AUTOSAR XML (schema 4-1-3)
standard types defined: boolean, uint16, boolean_CompuMethod, boolean_DataConstr, uint16_DataConstr, sint16, uint32, uint8
package /DataTypes
  impl type rt_Arry_uint16_10: category=ARRAY
    element rt_Arry_uint16_10: array-size=10, array-size-semantics=FIXED-SIZE, implementation-data-type=ImplementationDataTypes/uint16
package /RB/ApplicationSW/PT/ApplicationDataTypes
  application array data type rt_Array_U_q0p01_V_s16_10: category=ARRAY, sw-calibration-access=READ-WRITE
    element rt_Array_U_q0p01_V_s16_10: category=VALUE, type=U_q0p01_V_s16, array-size-semantics=FIXED-SIZE, max-number-of-elements=10
package /RB/ApplicationSW/PT/CompuMethods
  compu method CM_boolean: 0=FALSE, 1=TRUE
package /RB/ApplicationSW/PT/Constants
  12 x constant specification:
    EPBCalprDrvr_stPwrStgIndexStrt_C: value-spec=EPBCalprDrvr_stPwrStgIndexStrt_C:3
    EPBCalprDrvr_uAplySh2VoltMax_C: value-spec=0.5 V
    EPBCalprDrvr_uAplySh2VoltMin_C: value-spec=0 V
    EPBCalprDrvr_uHBrigVoltOffSet_C: value-spec=1 V
    EPBCalprDrvr_uPwrSuplyMax_C: value-spec=16 V
    EPBCalprDrvr_uPwrSuplyMin_C: value-spec=9 V
    EPBCalprDrvr_uRelsSh1VoltMax_C: value-spec=0.5 V
    EPBCalprDrvr_uRelsSh1VoltMin_C: value-spec=0 V
    EPBCalprDrvr_uStopSh1VoltMax_C: value-spec=0.5 V
    EPBCalprDrvr_uStopSh1VoltMin_C: value-spec=0 V
    EPBCalprDrvr_uStopSh2VoltMax_C: value-spec=0.5 V
    EPBCalprDrvr_uStopSh2VoltMin_C: value-spec=0 V
package /RB/ApplicationSW/PT/DataConstrs
  range DC_uint16: raw 0..65535
package /RB/ApplicationSW/PT/ImplementationDataTypes
  impl type rt_Array_sint16_10: category=ARRAY
    element rt_Array_sint16_10: array-size=10, array-size-semantics=FIXED-SIZE, implementation-data-type=sint16
  impl type rt_Array_uint32_2: category=ARRAY
    element rt_Array_uint32_2: array-size=2, array-size-semantics=FIXED-SIZE, implementation-data-type=uint32
package /RB/ApplicationSW/PT/Units
  unit NoUnit: factor-si-to-unit=1, offset-si-to-unit=0
package /SwAddrMethods
  sw addr method CALDATA_SWC: memory-allocation-keyword-policy=ADDR-METHOD-SHORT-NAME
package /UAES/ASW/ApplicationDataType
  4 x application array data type, all with category=ARRAY, sw-calibration-access=READ-WRITE:
    Array_Curr_q0p01_A_s16_10
      element Array_Curr_q0p01_A_s16_10: category=VALUE, type=Curr_q0p01_A_s16, array-size-semantics=FIXED-SIZE, max-number-of-elements=10
    Array_Curr_q0p01_A_u16_10
      element Array_Curr_q0p01_A_u16_10: category=VALUE, type=Curr_q0p01_A_u16, array-size-semantics=FIXED-SIZE, max-number-of-elements=10
    Array_U_q0p01_V_s16_10
      element Array_U_q0p01_V_s16_10: category=VALUE, type=U_q0p01_V_s16, array-size-semantics=FIXED-SIZE, max-number-of-elements=10
    Array_U_q0p01_V_u16_10
      element Array_U_q0p01_V_u16_10: category=VALUE, type=U_q0p01_V_u16, array-size-semantics=FIXED-SIZE, max-number-of-elements=10
  4 x app type, all with category=VALUE, sw-calibration-access=READ-WRITE:
    Curr_q0p01_A_s16: compu {phys=raw*0.01; unit A}, range phys -327.68..327.67
    Curr_q0p01_A_u16: compu {phys=raw*0.01; unit A}, range phys 0..655.35
    U_q0p01_V_s16: compu {phys=raw*0.01; unit V}, range phys -327.68..327.67
    U_q0p01_V_u16: compu {phys=raw*0.01; unit V}, range phys 0..655.35
package /UAES/ASW/DataConstrs
  range DC_boolean: raw 0..1
  range DC_sint16: raw -32768..32767
  range DC_uint16: raw 0..65535
  range DC_uint32: raw 0..4294967295
  range DC_uint8: raw 0..255
package /UAES/ASW/DataTypeMappingSets
  data type mapping set DTMS_EPBCalprDrvr_PwrStgFb
    data-type-maps:
      application-data-type=rt_Array_U_q0p01_V_s16_10, implementation-data-type=rt_Array_sint16_10
      application-data-type=Array_Curr_q0p01_A_s16_10, implementation-data-type=Array_sint16_10
      application-data-type=Array_Curr_q0p01_A_u16_10, implementation-data-type=Array_uint16_10
      application-data-type=Array_U_q0p01_V_s16_10, implementation-data-type=Array_sint16_10
      application-data-type=Array_U_q0p01_V_u16_10, implementation-data-type=Array_uint16_10
      application-data-type=Curr_q0p01_A_s16, implementation-data-type=sint16
      application-data-type=Curr_q0p01_A_u16, implementation-data-type=ImplementationDataTypes/uint16
      application-data-type=U_q0p01_V_s16, implementation-data-type=sint16
      application-data-type=U_q0p01_V_u16, implementation-data-type=ImplementationDataTypes/uint16
package /UAES/ASW/ImplementationDataTypes
  impl type Array_sint16_10: category=ARRAY
    element Array_sint16_10: array-size=10, array-size-semantics=FIXED-SIZE, implementation-data-type=sint16
  impl type Array_uint16_10: category=ARRAY
    element Array_uint16_10: array-size=10, array-size-semantics=FIXED-SIZE, implementation-data-type=ImplementationDataTypes/uint16
  impl type Array_uint32_2: category=ARRAY
    element Array_uint32_2: array-size=2, array-size-semantics=FIXED-SIZE, implementation-data-type=uint32
package /UAES/ASW/PortInterfaces
  client server interface IoHwAb_EPBHb
    9 x operation, all with possible-error=E_NOT_OK:
      Get_AD_Valid
        arg EPB_AD_Valid: category=VALUE, type=ImplementationDataTypes/boolean, direction=OUT
      Get_CS1_Val
        arg cs1_Val: category=ARRAY, type=rt_Arry_uint16_10, direction=OUT
      Get_CS2_Val
        arg cs2_Val: category=ARRAY, type=rt_Arry_uint16_10, direction=OUT
      Get_Diag
        arg EPBDiag_status: category=ARRAY, type=Array_uint32_2, direction=OUT
      Get_SH1_Val
        arg sh1_Val: category=ARRAY, type=Array_uint16_10, direction=OUT
      Get_SH2_Val
        arg sh2_Val: category=ARRAY, type=Array_uint16_10, direction=OUT
      Get_uBridge_Val
        arg uBridge_Val: category=ARRAY, type=Array_uint16_10, direction=OUT
      Set_Mod
        arg Hb_Mod: category=VALUE, type=uint8, direction=IN
      Set_Safemod
        arg Safemode_Mod: category=VALUE, type=ImplementationDataTypes/boolean, direction=IN
    error E_NOT_OK: error-code=1
  25 x sender receiver interface:
    EPBCalprDrvr_CurrMotDrvrCurr_a: invalidation-policy{data-element=EPBCalprDrvr_CurrMotDrvrCurr_a/Val, handle-invalid=DONT-INVALIDATE}
      data Val: category=ARRAY, sw-calibration-access=READ-ONLY, type=Array_Curr_q0p01_A_s16_10
    EPBCalprDrvr_CurrMotDrvrCurr_a_V3: invalidation-policy{data-element=EPBCalprDrvr_CurrMotDrvrCurr_a_V3/Val, handle-invalid=DONT-INVALIDATE}
      data Val: category=ARRAY, sw-calibration-access=READ-ONLY, type=Array_Curr_q0p01_A_u16_10
    EPBCalprDrvr_CurrMotDrvrCurrLocl_a: invalidation-policy{data-element=EPBCalprDrvr_CurrMotDrvrCurrLocl_a/Val, handle-invalid=DONT-INVALIDATE}
      data Val: category=ARRAY, sw-calibration-access=READ-ONLY, type=Array_Curr_q0p01_A_u16_10
    EPBCalprDrvr_flgCalprLineErrDeb: invalidation-policy{data-element=EPBCalprDrvr_flgCalprLineErrDeb/Val, handle-invalid=DONT-INVALIDATE}
      data Val: category=VALUE, sw-calibration-access=READ-ONLY, type=ImplementationDataTypes/boolean
    EPBCalprDrvr_flgCalprOLErrDeb: invalidation-policy{data-element=EPBCalprDrvr_flgCalprOLErrDeb/Val, handle-invalid=DONT-INVALIDATE}
      data Val: category=VALUE, sw-calibration-access=READ-ONLY, type=ImplementationDataTypes/boolean
    EPBCalprDrvr_flgCalprSCBErrDeb: invalidation-policy{data-element=EPBCalprDrvr_flgCalprSCBErrDeb/Val, handle-invalid=DONT-INVALIDATE}
      data Val: category=VALUE, sw-calibration-access=READ-ONLY, type=ImplementationDataTypes/boolean
    EPBCalprDrvr_flgCalprSCGErrDeb: invalidation-policy{data-element=EPBCalprDrvr_flgCalprSCGErrDeb/Val, handle-invalid=DONT-INVALIDATE}
      data Val: category=VALUE, sw-calibration-access=READ-ONLY, type=ImplementationDataTypes/boolean
    EPBCalprDrvr_flgClsdDrvrMos: invalidation-policy{data-element=EPBCalprDrvr_flgClsdDrvrMos/Val, handle-invalid=DONT-INVALIDATE}
      data Val: category=VALUE, sw-calibration-access=READ-ONLY, type=ImplementationDataTypes/boolean
    EPBCalprDrvr_flgHbrigLineErrDeb: invalidation-policy{data-element=EPBCalprDrvr_flgHbrigLineErrDeb/Val, handle-invalid=DONT-INVALIDATE}
      data Val: category=VALUE, sw-calibration-access=READ-ONLY, type=ImplementationDataTypes/boolean
    EPBCalprDrvr_flgHmiYelLmpOn: invalidation-policy{data-element=EPBCalprDrvr_flgHmiYelLmpOn/Val, handle-invalid=DONT-INVALIDATE}
      data Val: category=VALUE, sw-calibration-access=READ-ONLY, type=ImplementationDataTypes/boolean
    EPBCalprDrvr_flgRvpgOLErrDeb: invalidation-policy{data-element=EPBCalprDrvr_flgRvpgOLErrDeb/Val, handle-invalid=DONT-INVALIDATE}
      data Val: category=VALUE, sw-calibration-access=READ-ONLY, type=ImplementationDataTypes/boolean
    EPBCalprDrvr_flgRvpgPlsErrDeb: invalidation-policy{data-element=EPBCalprDrvr_flgRvpgPlsErrDeb/Val, handle-invalid=DONT-INVALIDATE}
      data Val: category=VALUE, sw-calibration-access=READ-ONLY, type=ImplementationDataTypes/boolean
    EPBCalprDrvr_stHostAvl: invalidation-policy{data-element=EPBCalprDrvr_stHostAvl/Val, handle-invalid=DONT-INVALIDATE}
      data Val: category=VALUE, sw-calibration-access=READ-ONLY, type=uint8
    EPBCalprDrvr_stHwDrvrCmd: invalidation-policy{data-element=EPBCalprDrvr_stHwDrvrCmd/Val, handle-invalid=DONT-INVALIDATE}
      data Val: category=VALUE, sw-calibration-access=READ-ONLY, type=uint8
    EPBCalprDrvr_stMosOffJudg: invalidation-policy{data-element=EPBCalprDrvr_stMosOffJudg/Val, handle-invalid=DONT-INVALIDATE}
      data Val: category=VALUE, sw-calibration-access=READ-ONLY, type=uint8
    EPBCalprDrvr_stMotDrvrSt: invalidation-policy{data-element=EPBCalprDrvr_stMotDrvrSt/Val, handle-invalid=DONT-INVALIDATE}
      data Val: category=VALUE, sw-calibration-access=READ-ONLY, type=uint8
    EPBCalprDrvr_stPwrSplySt: invalidation-policy{data-element=EPBCalprDrvr_stPwrSplySt/Val, handle-invalid=DONT-INVALIDATE}
      data Val: category=VALUE, sw-calibration-access=READ-ONLY, type=uint8
    EPBCalprDrvr_uHBrigVolt_a: invalidation-policy{data-element=EPBCalprDrvr_uHBrigVolt_a/Val, handle-invalid=DONT-INVALIDATE}
      data Val: category=ARRAY, sw-calibration-access=READ-ONLY, type=Array_U_q0p01_V_u16_10
    EPBCalprDrvr_uMotDrvrSplyAvrgVolt: invalidation-policy{data-element=EPBCalprDrvr_uMotDrvrSplyAvrgVolt/Val, handle-invalid=DONT-INVALIDATE}
      data Val: category=VALUE, sw-calibration-access=READ-ONLY, type=U_q0p01_V_u16
    EPBCalprDrvr_uMotDrvrSuplyVolt: invalidation-policy{data-element=EPBCalprDrvr_uMotDrvrSuplyVolt/Val, handle-invalid=DONT-INVALIDATE}
      data Val: category=VALUE, sw-calibration-access=READ-ONLY, type=U_q0p01_V_s16
    EPBCalprDrvr_uMotDrvrSuplyVolt_V3: invalidation-policy{data-element=EPBCalprDrvr_uMotDrvrSuplyVolt_V3/Val, handle-invalid=DONT-INVALIDATE}
      data Val: category=VALUE, sw-calibration-access=READ-ONLY, type=U_q0p01_V_u16
    EPBCalprDrvr_uMotDrvrVolt_a: invalidation-policy{data-element=EPBCalprDrvr_uMotDrvrVolt_a/Val, handle-invalid=DONT-INVALIDATE}
      data Val: category=ARRAY, sw-calibration-access=READ-ONLY, type=Array_U_q0p01_V_s16_10
    EPBCalprDrvr_uMotDrvrVoltLocl_a: invalidation-policy{data-element=EPBCalprDrvr_uMotDrvrVoltLocl_a/Val, handle-invalid=DONT-INVALIDATE}
      data Val: category=ARRAY, sw-calibration-access=READ-ONLY, type=rt_Array_U_q0p01_V_s16_10
    EPBCalprDrvr_uSh1Volt_a: invalidation-policy{data-element=EPBCalprDrvr_uSh1Volt_a/Val, handle-invalid=DONT-INVALIDATE}
      data Val: category=ARRAY, sw-calibration-access=READ-ONLY, type=Array_U_q0p01_V_u16_10
    EPBCalprDrvr_uSh2Volt_a: invalidation-policy{data-element=EPBCalprDrvr_uSh2Volt_a/Val, handle-invalid=DONT-INVALIDATE}
      data Val: category=ARRAY, sw-calibration-access=READ-ONLY, type=Array_U_q0p01_V_u16_10
package /UAES/ASW/SwComponentTypes
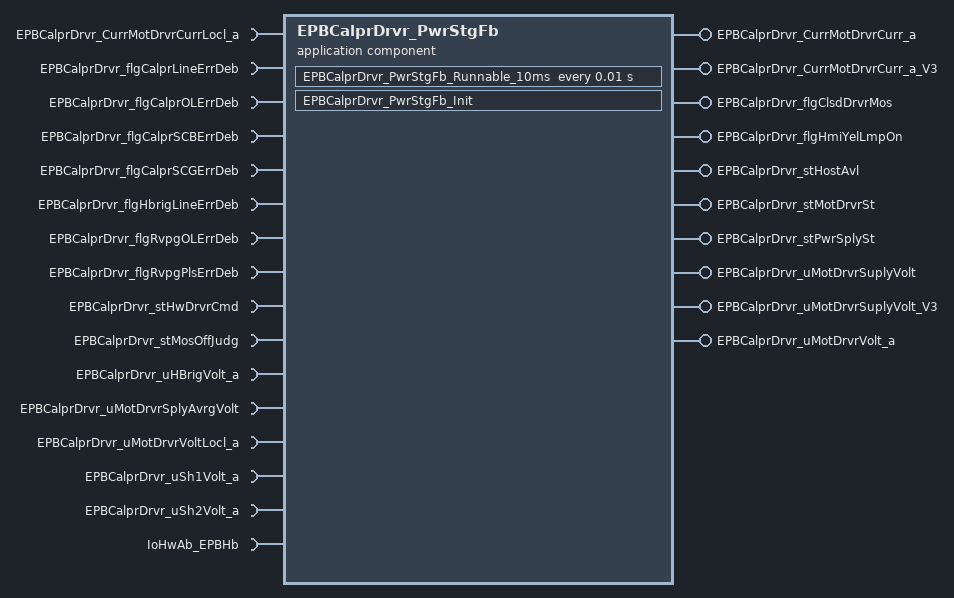
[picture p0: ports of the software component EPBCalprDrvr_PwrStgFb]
  application sw component type EPBCalprDrvr_PwrStgFb
    15 x require port:
      EPBCalprDrvr_CurrMotDrvrCurrLocl_a: nonqueued-receiver-com-spec{data-element=EPBCalprDrvr_CurrMotDrvrCurrLocl_a/Val, init-value=ComSpec04d326f9_854a79bc9e8ec665:10 x 0 A}, required-interface=EPBCalprDrvr_CurrMotDrvrCurrLocl_a
      EPBCalprDrvr_flgCalprLineErrDeb: nonqueued-receiver-com-spec{data-element=EPBCalprDrvr_flgCalprLineErrDeb/Val, init-value=ComSpec28eb8dd6_df283335803d315d:0}, required-interface=EPBCalprDrvr_flgCalprLineErrDeb
      EPBCalprDrvr_flgCalprOLErrDeb: nonqueued-receiver-com-spec{data-element=EPBCalprDrvr_flgCalprOLErrDeb/Val, init-value=ComSpeccc5a8cb5_4ed6c4668107c573:0}, required-interface=EPBCalprDrvr_flgCalprOLErrDeb
      EPBCalprDrvr_flgCalprSCBErrDeb: nonqueued-receiver-com-spec{data-element=EPBCalprDrvr_flgCalprSCBErrDeb/Val, init-value=ComSpeca196ac7a_66588703c52717d2:0}, required-interface=EPBCalprDrvr_flgCalprSCBErrDeb
      EPBCalprDrvr_flgCalprSCGErrDeb: nonqueued-receiver-com-spec{data-element=EPBCalprDrvr_flgCalprSCGErrDeb/Val, init-value=ComSpec815de22e_a43baf1ed2a030f3:0}, required-interface=EPBCalprDrvr_flgCalprSCGErrDeb
      EPBCalprDrvr_flgHbrigLineErrDeb: nonqueued-receiver-com-spec{data-element=EPBCalprDrvr_flgHbrigLineErrDeb/Val, init-value=ComSpec127366cc_e0cde48bb889a4e3:0}, required-interface=EPBCalprDrvr_flgHbrigLineErrDeb
      EPBCalprDrvr_flgRvpgOLErrDeb: nonqueued-receiver-com-spec{data-element=EPBCalprDrvr_flgRvpgOLErrDeb/Val, init-value=ComSpecedb32ece_dd05006a6dd768e6:0}, required-interface=EPBCalprDrvr_flgRvpgOLErrDeb
      EPBCalprDrvr_flgRvpgPlsErrDeb: nonqueued-receiver-com-spec{data-element=EPBCalprDrvr_flgRvpgPlsErrDeb/Val, init-value=ComSpecc3518dfb_07155b8be003ef41:0}, required-interface=EPBCalprDrvr_flgRvpgPlsErrDeb
      EPBCalprDrvr_stHwDrvrCmd: nonqueued-receiver-com-spec{data-element=EPBCalprDrvr_stHwDrvrCmd/Val, init-value=ComSpecf8dcf647_531a9a3c52d64e93:0}, required-interface=EPBCalprDrvr_stHwDrvrCmd
      EPBCalprDrvr_stMosOffJudg: nonqueued-receiver-com-spec{data-element=EPBCalprDrvr_stMosOffJudg/Val, init-value=ComSpec50af7012_f1fd4a6c0907b34b:0}, required-interface=EPBCalprDrvr_stMosOffJudg
      EPBCalprDrvr_uHBrigVolt_a: nonqueued-receiver-com-spec{data-element=EPBCalprDrvr_uHBrigVolt_a/Val, init-value=ComSpece093ef3e_f51da5a2f3bbfbb1:10 x 0 V}, required-interface=EPBCalprDrvr_uHBrigVolt_a
      EPBCalprDrvr_uMotDrvrSplyAvrgVolt: nonqueued-receiver-com-spec{data-element=EPBCalprDrvr_uMotDrvrSplyAvrgVolt/Val, init-value=0 V}, required-interface=EPBCalprDrvr_uMotDrvrSplyAvrgVolt
      EPBCalprDrvr_uMotDrvrVoltLocl_a: nonqueued-receiver-com-spec{data-element=EPBCalprDrvr_uMotDrvrVoltLocl_a/Val, init-value=10 x 0 V}, required-interface=EPBCalprDrvr_uMotDrvrVoltLocl_a
      EPBCalprDrvr_uSh1Volt_a: nonqueued-receiver-com-spec{data-element=EPBCalprDrvr_uSh1Volt_a/Val, init-value=ComSpec64c5832f_e000651616d126c6:10 x 0 V}, required-interface=EPBCalprDrvr_uSh1Volt_a
      EPBCalprDrvr_uSh2Volt_a: nonqueued-receiver-com-spec{data-element=EPBCalprDrvr_uSh2Volt_a/Val, init-value=ComSpec9bae2baa_1418055b20c87e5d:10 x 0 V}, required-interface=EPBCalprDrvr_uSh2Volt_a
    10 x provide port:
      EPBCalprDrvr_CurrMotDrvrCurr_a: nonqueued-sender-com-spec{data-element=EPBCalprDrvr_CurrMotDrvrCurr_a/Val, init-value=ComSpec1249f747_d1fdc2f777adf1e2:10 x 0 A}, provided-interface=EPBCalprDrvr_CurrMotDrvrCurr_a
      EPBCalprDrvr_CurrMotDrvrCurr_a_V3: nonqueued-sender-com-spec{data-element=EPBCalprDrvr_CurrMotDrvrCurr_a_V3/Val, init-value=ComSpecbd657f9a_7bd1f2e1d8539795:10 x 0 A}, provided-interface=EPBCalprDrvr_CurrMotDrvrCurr_a_V3
      EPBCalprDrvr_flgClsdDrvrMos: nonqueued-sender-com-spec{data-element=EPBCalprDrvr_flgClsdDrvrMos/Val, init-value=ComSpec78b9b2fa_2bd4bb19a0f7df80:0}, provided-interface=EPBCalprDrvr_flgClsdDrvrMos
      EPBCalprDrvr_flgHmiYelLmpOn: nonqueued-sender-com-spec{data-element=EPBCalprDrvr_flgHmiYelLmpOn/Val, init-value=ComSpecc9547617_96a615b82ff86366:0}, provided-interface=EPBCalprDrvr_flgHmiYelLmpOn
      EPBCalprDrvr_stHostAvl: nonqueued-sender-com-spec{data-element=EPBCalprDrvr_stHostAvl/Val, init-value=ComSpec5833e355_c3467058c7969c7e:0}, provided-interface=EPBCalprDrvr_stHostAvl
      EPBCalprDrvr_stMotDrvrSt: nonqueued-sender-com-spec{data-element=EPBCalprDrvr_stMotDrvrSt/Val, init-value=ComSpeceaa41e8d_8c4e0f8c54df2944:0}, provided-interface=EPBCalprDrvr_stMotDrvrSt
      EPBCalprDrvr_stPwrSplySt: nonqueued-sender-com-spec{data-element=EPBCalprDrvr_stPwrSplySt/Val, init-value=ComSpec5c829aed_178fb1372e8ab1e9:0}, provided-interface=EPBCalprDrvr_stPwrSplySt
      EPBCalprDrvr_uMotDrvrSuplyVolt: nonqueued-sender-com-spec{data-element=EPBCalprDrvr_uMotDrvrSuplyVolt/Val, init-value=0 V}, provided-interface=EPBCalprDrvr_uMotDrvrSuplyVolt
      EPBCalprDrvr_uMotDrvrSuplyVolt_V3: nonqueued-sender-com-spec{data-element=EPBCalprDrvr_uMotDrvrSuplyVolt_V3/Val, init-value=0 V}, provided-interface=EPBCalprDrvr_uMotDrvrSuplyVolt_V3
      EPBCalprDrvr_uMotDrvrVolt_a: nonqueued-sender-com-spec{data-element=EPBCalprDrvr_uMotDrvrVolt_a/Val, init-value=ComSpec42ca1696_8c5f454c72e39372:10 x 0 V}, provided-interface=EPBCalprDrvr_uMotDrvrVolt_a
    require port IoHwAb_EPBHb: required-interface=IoHwAb_EPBHb
    behavior EPBCalprDrvr_PwrStgFb_InternalBehavior: data-type-mapping=DTMS_EPBCalprDrvr_PwrStgFb, handle-termination-and-restart=NO-SUPPORT
      ar-typed-per-instance-memorys:
        27 x data, all with sw-calibration-access=READ-ONLY:
          EPBC_EPBCalprDrvr_stDiagInfor_a: category=ARRAY, type=rt_Array_uint32_2
          EPBCalprDrvr_stDiagInforErrArry: category=VALUE, type=uint32
          E_EPBCalprDrvr_stDiagInforErrAr: category=VALUE, type=uint32
          EPBCalprDrvr_stDiagInforClsdMos: category=VALUE, type=uint32
          EPBCalprDrvr_EPBCalprDrvr_uSH1: category=VALUE, type=U_q0p01_V_u16
          EPBCalprDrvr_EPBCalprDrvr_uSH2: category=VALUE, type=U_q0p01_V_u16
          EPBCalprDrv_EPBCalprDrvr_uHBrig: category=VALUE, type=U_q0p01_V_u16
          EPBC_EPBCalprDrvr_uHBrigVoltMax: category=VALUE, type=U_q0p01_V_u16
          EPBC_EPBCalprDrvr_uHBrigVoltMin: category=VALUE, type=U_q0p01_V_u16
          EPBCalp_EPBCalprDrvr_stStopJudg: category=VALUE, type=uint8
          EPBCalp_EPBCalprDrvr_stAplyJudg: category=VALUE, type=uint8
          EPBCalp_EPBCalprDrvr_stRelsJudg: category=VALUE, type=uint8
          EPBCalprD_EPBCalprDrvr_flgADVld: category=VALUE, type=ImplementationDataTypes/boolean
          EPBCalprDrvr_flgADCUntrustedDeb: category=VALUE, type=ImplementationDataTypes/boolean
          EPBCalprDrvr_flgCurrAdcPlsChkEr: category=VALUE, type=ImplementationDataTypes/boolean
          EP_EPBCalprDrvr_flgVSCPUVErrDeb: category=VALUE, type=ImplementationDataTypes/boolean
          E_EPBCalprDrvr_flgSyncChkErrDeb: category=VALUE, type=ImplementationDataTypes/boolean
          EP_EPBCalprDrvr_flgADSyncErrDeb: category=VALUE, type=ImplementationDataTypes/boolean
          EPBCalprDrvr_flgSPIComSetUpInvl: category=VALUE, type=ImplementationDataTypes/boolean
          EPBCalprDrvr_flgADCDateInvldDeb: category=VALUE, type=ImplementationDataTypes/boolean
          EP_EPBCalprDrvr_flgDiagInforErr: category=VALUE, type=ImplementationDataTypes/boolean
          EPBCalprDrvr_flgAffctHostAvlDeb: category=VALUE, type=ImplementationDataTypes/boolean
          EPBCa_EPBCalprDrvr_flgMosAllOff: category=VALUE, type=ImplementationDataTypes/boolean
          EPBCalprDrvr_flgHwDrvrSafetyCtr: category=VALUE, type=ImplementationDataTypes/boolean
          EPBCalprDrvr_flgStopVoltChkSts: category=VALUE, type=ImplementationDataTypes/boolean
          EPBCalprDrvr_flgAplyVoltChkSts: category=VALUE, type=ImplementationDataTypes/boolean
          EPBCalprDrvr_flgRelsVoltChkSts: category=VALUE, type=ImplementationDataTypes/boolean
      init event EPBCalprDrvr_PwrStgFb_InitEvent: start-on-event=EPBCalprDrvr_PwrStgFb_Init
      timing event TMT_EPBCalprDrvr_PwrStgFb_Runnable_10ms: start-on-event=EPBCalprDrvr_PwrStgFb_Runnable_10ms, period=0.01
      runnable EPBCalprDrvr_PwrStgFb_Init
      runnable EPBCalprDrvr_PwrStgFb_Runnable_10ms
        data-read-access:
          15 x access:
            IN_EPBCalprDrvr_CurrMotDrvrCurrLocl_a_Val: accessed-variable=EPBCalprDrvr_CurrMotDrvrCurrLocl_a.Val
            IN_EPBCalprDrvr_flgCalprLineErrDeb_Val: accessed-variable=EPBCalprDrvr_flgCalprLineErrDeb.Val
            IN_EPBCalprDrvr_flgCalprOLErrDeb_Val: accessed-variable=EPBCalprDrvr_flgCalprOLErrDeb.Val
            IN_EPBCalprDrvr_flgCalprSCBErrDeb_Val: accessed-variable=EPBCalprDrvr_flgCalprSCBErrDeb.Val
            IN_EPBCalprDrvr_flgCalprSCGErrDeb_Val: accessed-variable=EPBCalprDrvr_flgCalprSCGErrDeb.Val
            IN_EPBCalprDrvr_flgHbrigLineErrDeb_Val: accessed-variable=EPBCalprDrvr_flgHbrigLineErrDeb.Val
            IN_EPBCalprDrvr_flgRvpgOLErrDeb_Val: accessed-variable=EPBCalprDrvr_flgRvpgOLErrDeb.Val
            IN_EPBCalprDrvr_flgRvpgPlsErrDeb_Val: accessed-variable=EPBCalprDrvr_flgRvpgPlsErrDeb.Val
            IN_EPBCalprDrvr_stHwDrvrCmd_Val: accessed-variable=EPBCalprDrvr_stHwDrvrCmd.Val
            IN_EPBCalprDrvr_stMosOffJudg_Val: accessed-variable=EPBCalprDrvr_stMosOffJudg.Val
            IN_EPBCalprDrvr_uHBrigVolt_a_Val: accessed-variable=EPBCalprDrvr_uHBrigVolt_a.Val
            IN_EPBCalprDrvr_uMotDrvrSplyAvrgVolt_Val: accessed-variable=EPBCalprDrvr_uMotDrvrSplyAvrgVolt.Val
            IN_EPBCalprDrvr_uMotDrvrVoltLocl_a_Val: accessed-variable=EPBCalprDrvr_uMotDrvrVoltLocl_a.Val
            IN_EPBCalprDrvr_uSh1Volt_a_Val: accessed-variable=EPBCalprDrvr_uSh1Volt_a.Val
            IN_EPBCalprDrvr_uSh2Volt_a_Val: accessed-variable=EPBCalprDrvr_uSh2Volt_a.Val
        data-write-access:
          10 x access:
            OUT_EPBCalprDrvr_CurrMotDrvrCurr_a_V3_Val: accessed-variable=EPBCalprDrvr_CurrMotDrvrCurr_a_V3.Val
            OUT_EPBCalprDrvr_CurrMotDrvrCurr_a_Val: accessed-variable=EPBCalprDrvr_CurrMotDrvrCurr_a.Val
            OUT_EPBCalprDrvr_flgClsdDrvrMos_Val: accessed-variable=EPBCalprDrvr_flgClsdDrvrMos.Val
            OUT_EPBCalprDrvr_flgHmiYelLmpOn_Val: accessed-variable=EPBCalprDrvr_flgHmiYelLmpOn.Val
            OUT_EPBCalprDrvr_stHostAvl_Val: accessed-variable=EPBCalprDrvr_stHostAvl.Val
            OUT_EPBCalprDrvr_stMotDrvrSt_Val: accessed-variable=EPBCalprDrvr_stMotDrvrSt.Val
            OUT_EPBCalprDrvr_uMotDrvrSuplyVolt_V3_Val: accessed-variable=EPBCalprDrvr_uMotDrvrSuplyVolt_V3.Val
            OUT_EPBCalprDrvr_uMotDrvrSuplyVolt_Val: accessed-variable=EPBCalprDrvr_uMotDrvrSuplyVolt.Val
            OUT_EPBCalprDrvr_uMotDrvrVolt_a_Val: accessed-variable=EPBCalprDrvr_uMotDrvrVolt_a.Val
            OUT_EPBCalprDrvr_stPwrSplySt_Val: accessed-variable=EPBCalprDrvr_stPwrSplySt.Val
        12 x parameter access:
          SCALPRM_EPBCalprDrvr_stPwrStgIndexStrt_C: accessed-parameter=EPBCalprDrvr_stPwrStgIndexStrt_C
          SCALPRM_EPBCalprDrvr_uAplySh2VoltMax_C: accessed-parameter=EPBCalprDrvr_uAplySh2VoltMax_C
          SCALPRM_EPBCalprDrvr_uAplySh2VoltMin_C: accessed-parameter=EPBCalprDrvr_uAplySh2VoltMin_C
          SCALPRM_EPBCalprDrvr_uHBrigVoltOffSet_C: accessed-parameter=EPBCalprDrvr_uHBrigVoltOffSet_C
          SCALPRM_EPBCalprDrvr_uPwrSuplyMax_C: accessed-parameter=EPBCalprDrvr_uPwrSuplyMax_C
          SCALPRM_EPBCalprDrvr_uPwrSuplyMin_C: accessed-parameter=EPBCalprDrvr_uPwrSuplyMin_C
          SCALPRM_EPBCalprDrvr_uRelsSh1VoltMax_C: accessed-parameter=EPBCalprDrvr_uRelsSh1VoltMax_C
          SCALPRM_EPBCalprDrvr_uRelsSh1VoltMin_C: accessed-parameter=EPBCalprDrvr_uRelsSh1VoltMin_C
          SCALPRM_EPBCalprDrvr_uStopSh1VoltMax_C: accessed-parameter=EPBCalprDrvr_uStopSh1VoltMax_C
          SCALPRM_EPBCalprDrvr_uStopSh1VoltMin_C: accessed-parameter=EPBCalprDrvr_uStopSh1VoltMin_C
          SCALPRM_EPBCalprDrvr_uStopSh2VoltMax_C: accessed-parameter=EPBCalprDrvr_uStopSh2VoltMax_C
          SCALPRM_EPBCalprDrvr_uStopSh2VoltMin_C: accessed-parameter=EPBCalprDrvr_uStopSh2VoltMin_C
        sync call SC_IoHwAb_EPBHb_Get_AD_Valid: operation=IoHwAb_EPBHb.Get_AD_Valid, timeout=0
        sync call SC_IoHwAb_EPBHb_Get_Diag: operation=IoHwAb_EPBHb.Get_Diag, timeout=0
      shared-parameters:
        12 x parameter data prototype, all with category=VALUE, sw-addr-method=CALDATA_SWC, sw-calibration-access=READ-WRITE:
          EPBCalprDrvr_stPwrStgIndexStrt_C: type=uint8, init-value=constant-reference={short-label=EPBCalprDrvr_stPwrStgIndexStrt_C, constant=EPBCalprDrvr_stPwrStgIndexStrt_C}
          EPBCalprDrvr_uAplySh2VoltMax_C: type=U_q0p01_V_u16, init-value=constant-reference={short-label=EPBCalprDrvr_uAplySh2VoltMax_C, constant=EPBCalprDrvr_uAplySh2VoltMax_C}
          EPBCalprDrvr_uAplySh2VoltMin_C: type=U_q0p01_V_u16, init-value=constant-reference={short-label=EPBCalprDrvr_uAplySh2VoltMin_C, constant=EPBCalprDrvr_uAplySh2VoltMin_C}
          EPBCalprDrvr_uHBrigVoltOffSet_C: type=U_q0p01_V_u16, init-value=constant-reference={short-label=EPBCalprDrvr_uHBrigVoltOffSet_C, constant=EPBCalprDrvr_uHBrigVoltOffSet_C}
          EPBCalprDrvr_uPwrSuplyMax_C: type=U_q0p01_V_u16, init-value=constant-reference={short-label=EPBCalprDrvr_uPwrSuplyMax_C, constant=EPBCalprDrvr_uPwrSuplyMax_C}
          EPBCalprDrvr_uPwrSuplyMin_C: type=U_q0p01_V_u16, init-value=constant-reference={short-label=EPBCalprDrvr_uPwrSuplyMin_C, constant=EPBCalprDrvr_uPwrSuplyMin_C}
          EPBCalprDrvr_uRelsSh1VoltMax_C: type=U_q0p01_V_u16, init-value=constant-reference={short-label=EPBCalprDrvr_uRelsSh1VoltMax_C, constant=EPBCalprDrvr_uRelsSh1VoltMax_C}
          EPBCalprDrvr_uRelsSh1VoltMin_C: type=U_q0p01_V_u16, init-value=constant-reference={short-label=EPBCalprDrvr_uRelsSh1VoltMin_C, constant=EPBCalprDrvr_uRelsSh1VoltMin_C}
          EPBCalprDrvr_uStopSh1VoltMax_C: type=U_q0p01_V_u16, init-value=constant-reference={short-label=EPBCalprDrvr_uStopSh1VoltMax_C, constant=EPBCalprDrvr_uStopSh1VoltMax_C}
          EPBCalprDrvr_uStopSh1VoltMin_C: type=U_q0p01_V_u16, init-value=constant-reference={short-label=EPBCalprDrvr_uStopSh1VoltMin_C, constant=EPBCalprDrvr_uStopSh1VoltMin_C}
          EPBCalprDrvr_uStopSh2VoltMax_C: type=U_q0p01_V_u16, init-value=constant-reference={short-label=EPBCalprDrvr_uStopSh2VoltMax_C, constant=EPBCalprDrvr_uStopSh2VoltMax_C}
          EPBCalprDrvr_uStopSh2VoltMin_C: type=U_q0p01_V_u16, init-value=constant-reference={short-label=EPBCalprDrvr_uStopSh2VoltMin_C, constant=EPBCalprDrvr_uStopSh2VoltMin_C}
  swc implementation EPBCalprDrvr_PwrStgFb_imp: programming-language=C, sw-version=1.10.1, used-code-generator=Embedded Coder 7.5 (R2020b) 29-Jul-2020, vendor-id=0, behavior=EPBCalprDrvr_PwrStgFb_InternalBehavior
    code-descriptors:
      code Code
        artifact-descriptors:
          short-label=EPBCalprDrvr_PwrStgFb_c, category=SWSRC
          short-label=EPBCalprDrvr_PwrStgFb_h, category=SWHDR
          short-label=EPBCalprDrvr_PwrStgFb_private_h, category=SWHDR
          short-label=EPBCalprDrvr_PwrStgFb_types_h, category=SWHDR
          short-label=rtwtypes_h, category=SWHDR
    resource consumption RsrcCons_EPBCalprDrvr_PwrStgFb
package /UAES/ASW/Units
  unit A: display-name=A, factor-si-to-unit=1, offset-si-to-unit=0
  unit V: display-name=V, factor-si-to-unit=1, offset-si-to-unit=0
